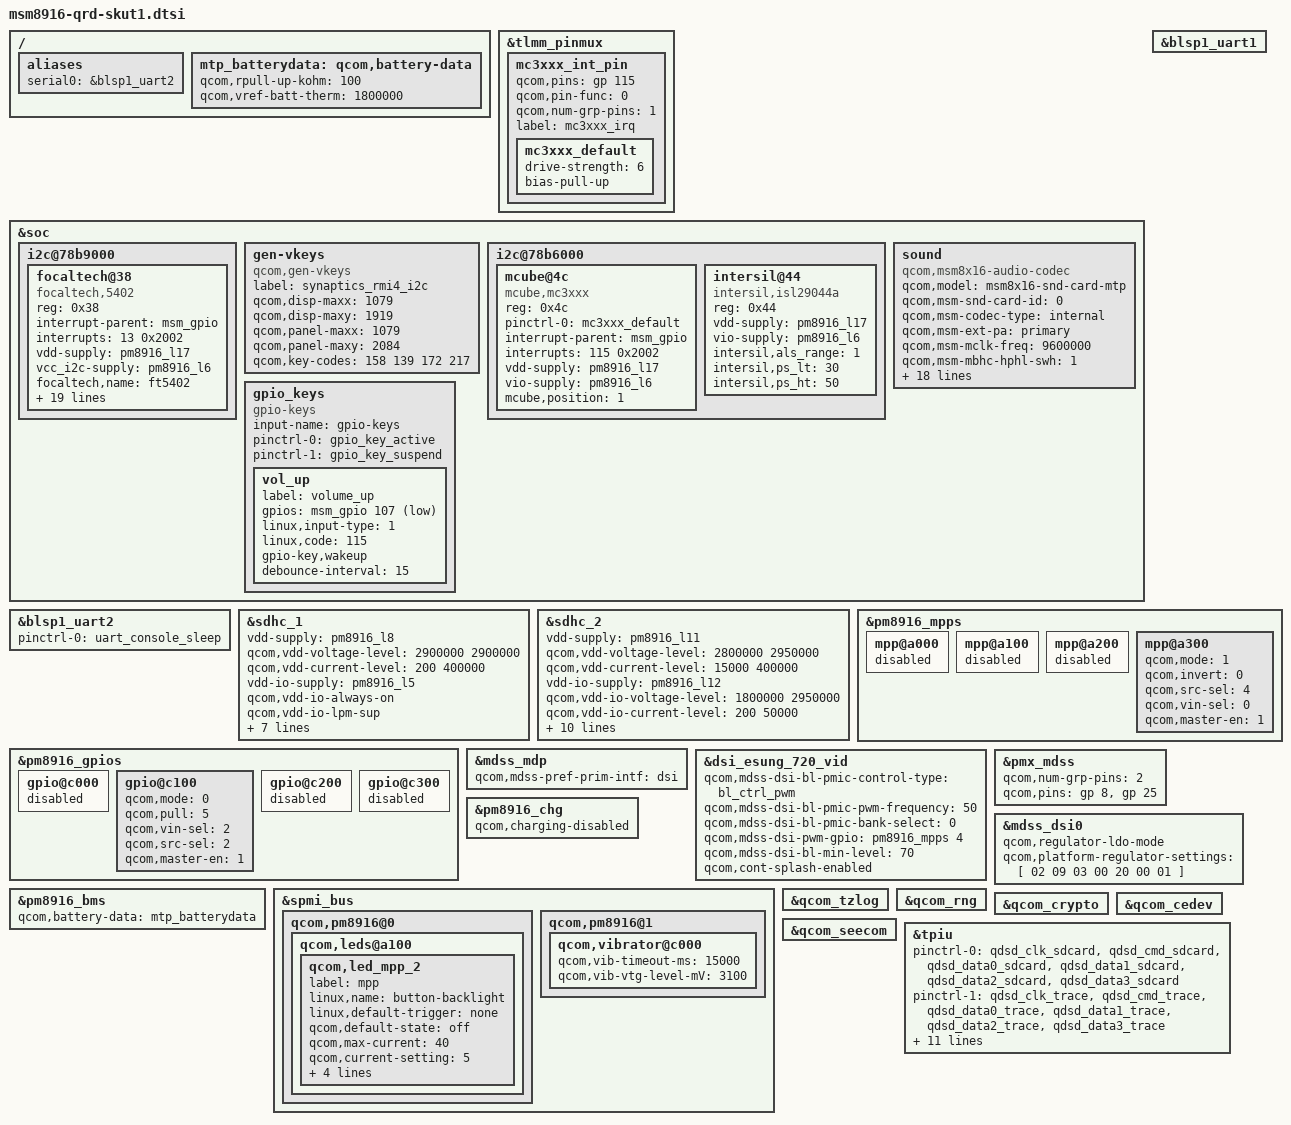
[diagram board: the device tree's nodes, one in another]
/* Copyright (c) 2014, The Linux Foundation. All rights reserved.
 *
 * This program is free software; you can redistribute it and/or modify
 * it under the terms of the GNU General Public License version 2 and
 * only version 2 as published by the Free Software Foundation.
 *
 * This program is distributed in the hope that it will be useful,
 * but WITHOUT ANY WARRANTY; without even the implied warranty of
 * MERCHANTABILITY or FITNESS FOR A PARTICULAR PURPOSE.  See the
 * GNU General Public License for more details.
 */

#include "msm8916.dtsi"
#include "msm8916-pinctrl.dtsi"
#include "msm8916-camera-sensor-skut1.dtsi"
#include "dsi-panel-esung-720p-video.dtsi"

/ {
	aliases {
		serial0 = &blsp1_uart2;
	};
};
&tlmm_pinmux {
	mc3xxx_int_pin {
		qcom,pins = <&gp 115>;
		qcom,pin-func = <0>;
		qcom,num-grp-pins = <1>;
		label = "mc3xxx_irq";
		mc3xxx_default: mc3xxx_default {
			  drive-strength = <6>;
			  bias-pull-up;
	  };
 	};
};
&soc {
	i2c@78b9000 { /* BLSP1 QUP5 */
		
		focaltech@38 {
			compatible = "focaltech,5402";
			reg = <0x38>;
			interrupt-parent = <&msm_gpio>;
			interrupts = <13 0x2002>;
			vdd-supply = <&pm8916_l17>;
			vcc_i2c-supply = <&pm8916_l6>;
			focaltech,name = "ft5402";
			focaltech,family-id = <0x55>;
			focaltech,reset-gpio = <&msm_gpio 12 0x0>;
			focaltech,irq-gpio = <&msm_gpio 13 0x2002>;
			focaltech,display-coords = <0 0 1280 800>;
			focaltech,panel-coords = <0 0 1280 800>;
			focaltech,button-map= <139 102 158>;
			focaltech,no-force-update;
			focaltech,i2c-pull-up;
			focaltech,group-id = <1>;
			focaltech,hard-reset-delay-ms = <20>;
			focaltech,soft-reset-delay-ms = <200>;
			focaltech,num-max-touches = <5>;
			focaltech,fw-name = "ft_8226_qrd_1080p_fw.bin";
			focaltech,fw-delay-aa-ms = <50>;
			focaltech,fw-delay-55-ms = <30>;
			focaltech,fw-upgrade-id1 = <0x79>;
			focaltech,fw-upgrade-id2 = <0x03>;
			focaltech,fw-delay-readid-ms = <10>;
			focaltech,fw-delay-era-flsh-ms = <2000>;
		};
	};

	gen-vkeys {
		compatible = "qcom,gen-vkeys";
		label = "synaptics_rmi4_i2c";
		qcom,disp-maxx = <1079>;
		qcom,disp-maxy = <1919>;
		qcom,panel-maxx = <1079>;
		qcom,panel-maxy = <2084>;
		qcom,key-codes = <158 139 172 217>;
	};

	i2c@78b6000 { /* BLSP1 QUP6 */


	mcube@4c { /* Accelerometer sensor */
		compatible = "mcube,mc3xxx";
		reg = <0x4c>;
		pinctrl-names = "default";
		pinctrl-0 = <&mc3xxx_default>;
		interrupt-parent = <&msm_gpio>;
		interrupts = <115 0x2002>;
		vdd-supply = <&pm8916_l17>;
		vio-supply = <&pm8916_l6>;
		mcube,position = <1>;
	};

        intersil@44 {
			compatible = "intersil,isl29044a";
			reg = <0x44>;
			vdd-supply = <&pm8916_l17>;
 		  vio-supply = <&pm8916_l6>;           
 		  intersil,als_range = <1>;       
        intersil,ps_lt = <30>;           
        intersil,ps_ht = <50>;          
		};
	};
	

	sound {
		compatible = "qcom,msm8x16-audio-codec";
		qcom,model = "msm8x16-snd-card-mtp";
		qcom,msm-snd-card-id = <0>;
		qcom,msm-codec-type = "internal";
		qcom,msm-ext-pa = "primary";
		qcom,msm-mclk-freq = <9600000>;
		qcom,msm-mbhc-hphl-swh = <1>;
		qcom,msm-mbhc-gnd-swh = <0>;
		qcom,msm-hs-micbias-type = "internal";
		qcom,audio-routing =
			"RX_BIAS", "MCLK",
			"SPK_RX_BIAS", "MCLK",
			"INT_LDO_H", "MCLK",
			"MIC BIAS External", "Handset Mic",
			"MIC BIAS Internal2", "Headset Mic",
			"MIC BIAS External", "Secondary Mic",
			"AMIC1", "MIC BIAS External",
			"AMIC2", "MIC BIAS Internal2",
			"AMIC3", "MIC BIAS External";
		pinctrl-names = "cdc_lines_act",
				"cdc_lines_sus",
				"cdc_lines_sec_ext_act",
				"cdc_lines_sec_ext_sus",
				"cross_conn_det_act",
				"cross_conn_det_sus";
		pinctrl-0 = <&cdc_pdm_lines_act>;
		pinctrl-1 = <&cdc_pdm_lines_sus>;
		pinctrl-2 = <&cdc_pdm_lines_act &cdc_ext_pa_act
						&cdc_ext_pa_ws_act>;
		pinctrl-3 = <&cdc_pdm_lines_sus &cdc_ext_pa_sus
						&cdc_ext_pa_ws_sus>;
		pinctrl-4 = <&cross_conn_det_act>;
		pinctrl-5 = <&cross_conn_det_sus>;
		qcom,cdc-us-euro-gpios = <&msm_gpio 110 0>;
	};
};

&blsp1_uart2 {
	status = "ok";
	pinctrl-names = "default";
	pinctrl-0 = <&uart_console_sleep>;
};

&soc {
	gpio_keys {
		compatible = "gpio-keys";
		input-name = "gpio-keys";
		pinctrl-names = "tlmm_gpio_key_active","tlmm_gpio_key_suspend";
		pinctrl-0 = <&gpio_key_active>;
		pinctrl-1 = <&gpio_key_suspend>;

		vol_up {
			label = "volume_up";
			gpios = <&msm_gpio 107 0x1>;
			linux,input-type = <1>;
			linux,code = <115>;
			gpio-key,wakeup;
			debounce-interval = <15>;
		};
	};
};

&blsp1_uart1 {
	status = "ok";
};

&sdhc_1 {
	vdd-supply = <&pm8916_l8>;
	qcom,vdd-voltage-level = <2900000 2900000>;
	qcom,vdd-current-level = <200 400000>;

	vdd-io-supply = <&pm8916_l5>;
	qcom,vdd-io-always-on;
	qcom,vdd-io-lpm-sup;
	qcom,vdd-io-voltage-level = <1800000 1800000>;
	qcom,vdd-io-current-level = <200 60000>;

	pinctrl-names = "active", "sleep";
	pinctrl-0 = <&sdc1_clk_on &sdc1_cmd_on &sdc1_data_on>;
	pinctrl-1 = <&sdc1_clk_off &sdc1_cmd_off &sdc1_data_off>;

	qcom,nonremovable;

	status = "ok";
};

&sdhc_2 {
	vdd-supply = <&pm8916_l11>;
	qcom,vdd-voltage-level = <2800000 2950000>;
	qcom,vdd-current-level = <15000 400000>;

	vdd-io-supply = <&pm8916_l12>;
	qcom,vdd-io-voltage-level = <1800000 2950000>;
	qcom,vdd-io-current-level = <200 50000>;

	pinctrl-names = "active", "sleep";
	pinctrl-0 = <&sdc2_clk_on &sdc2_cmd_on &sdc2_data_on &sdc2_cd_on>;
	pinctrl-1 = <&sdc2_clk_off &sdc2_cmd_off &sdc2_data_off &sdc2_cd_off>;

	#address-cells = <0>;
	interrupt-parent = <&sdhc_2>;
	interrupts = <0 1 2>;
	#interrupt-cells = <1>;
	interrupt-map-mask = <0xffffffff>;
	interrupt-map = <0 &intc 0 125 0
			1 &intc 0 221 0
			2 &msm_gpio 38 0>;
	interrupt-names = "hc_irq", "pwr_irq", "status_irq";
	cd-gpios = <&msm_gpio 38 0x1>;

	status = "ok";
};

&pm8916_mpps {
	mpp@a000 { /* MPP 1 */
		/* VDD_PX */
		status = "disabled";
	};

	mpp@a100 { /* MPP 2 */
		/* HR LED */
		status = "disabled";
	};

	mpp@a200 { /* MPP 3 */
		/* VREF DAC */
		status = "disabled";
	};

	mpp@a300 { /* MPP 4 */
		/* Backlight PWM */
		qcom,mode = <1>;		/* Digital output */
		qcom,invert = <0>;		/* Disable invert */
		qcom,src-sel = <4>;		/* DTEST1 */
		qcom,vin-sel = <0>;		/* VPH_PWR */
		qcom,master-en = <1>;		/* Enable MPP */
	};
};

&pm8916_gpios {
	gpio@c000 { /* GPIO 1 */
		/* Battery UICC Alarm */
		status = "disabled";
	};

	gpio@c100 { /* GPIO 2 */
		/* NFC_CLK_REQ */
		qcom,mode = <0>; /* QPNP_PIN_MODE_DIG_IN */
		qcom,pull = <5>; /* QPNP_PIN_PULL_NO */
		qcom,vin-sel = <2>; /* QPNP_PIN_VIN2 */
		qcom,src-sel = <2>; /* QPNP_PIN_SEL_FUNC_1 */
		qcom,master-en = <1>;
	};

	gpio@c200 { /* GPIO 3 */
		/* External regulator control for WTR */
		status = "disabled";
	};

	gpio@c300 { /* GPIO 4 */
		/* External regulator control for APC */
		status = "disabled";
	};
};



&mdss_mdp {
	qcom,mdss-pref-prim-intf = "dsi";
};

&dsi_esung_720_vid {
	qcom,mdss-dsi-bl-pmic-control-type = "bl_ctrl_pwm";
	qcom,mdss-dsi-bl-pmic-pwm-frequency = <50>;
	qcom,mdss-dsi-bl-pmic-bank-select = <0>;
	qcom,mdss-dsi-pwm-gpio = <&pm8916_mpps 4 0>;
	qcom,mdss-dsi-bl-min-level = <70>;

};

&pmx_mdss {
	qcom,num-grp-pins = <2>;
	qcom,pins = <&gp 8>, <&gp 25>;
};

&mdss_dsi0 {
  qcom,regulator-ldo-mode;
  qcom,platform-regulator-settings=[ 02 09 03 00 20 00 01 ];
};  
&dsi_esung_720_vid {
       qcom,cont-splash-enabled;
};

&pm8916_chg {
	status = "ok";
	qcom,charging-disabled;
};



/ {
	mtp_batterydata: qcom,battery-data {
		qcom,rpull-up-kohm = <100>;
		qcom,vref-batt-therm = <1800000>;

		#include "batterydata-palladium.dtsi"
	};
};

&pm8916_bms {
	status = "ok";
	qcom,battery-data = <&mtp_batterydata>;
};

&spmi_bus {
	qcom,pm8916@0 {
		qcom,leds@a100 {
			status = "okay";
			qcom,led_mpp_2 {
				label = "mpp";
				linux,name = "button-backlight";
				linux,default-trigger = "none";
				qcom,default-state = "off";
				qcom,max-current = <40>;
				qcom,current-setting = <5>;
				qcom,id = <6>;
				qcom,mode = "manual";
				qcom,source-sel = <1>;
				qcom,mode-ctrl = <0x60>;
			};
		};
	};
};

&qcom_tzlog {
	status = "okay";
};

&qcom_rng {
	status = "okay";
};

&qcom_crypto {
	status = "okay";
};

&qcom_cedev {
	status = "okay";
};

&qcom_seecom {
	status = "okay";
};

/* CoreSight */
&tpiu {
      pinctrl-names = "sdcard", "trace", "swduart",
		      "swdtrc", "jtag", "spmi";
       /* NIDnT */
      pinctrl-0 = <&qdsd_clk_sdcard &qdsd_cmd_sdcard
                  &qdsd_data0_sdcard &qdsd_data1_sdcard
                  &qdsd_data2_sdcard &qdsd_data3_sdcard>;
      pinctrl-1 = <&qdsd_clk_trace &qdsd_cmd_trace
                  &qdsd_data0_trace &qdsd_data1_trace
                  &qdsd_data2_trace &qdsd_data3_trace>;
      pinctrl-2 = <&qdsd_cmd_swduart &qdsd_data0_swduart
                  &qdsd_data1_swduart &qdsd_data2_swduart
                  &qdsd_data3_swduart>;
      pinctrl-3 = <&qdsd_clk_swdtrc &qdsd_cmd_swdtrc
                  &qdsd_data0_swdtrc &qdsd_data1_swdtrc
                  &qdsd_data2_swdtrc &qdsd_data3_swdtrc>;
      pinctrl-4 = <&qdsd_cmd_jtag &qdsd_data0_jtag
                  &qdsd_data1_jtag &qdsd_data2_jtag
                  &qdsd_data3_jtag>;
      pinctrl-5 = <&qdsd_clk_spmi &qdsd_cmd_spmi
                  &qdsd_data0_spmi &qdsd_data3_spmi>;
};

&spmi_bus {
	qcom,pm8916@1 {
		qcom,vibrator@c000 {
			status = "okay";
			qcom,vib-timeout-ms = <15000>;
			qcom,vib-vtg-level-mV = <3100>;
		};
	};
};
